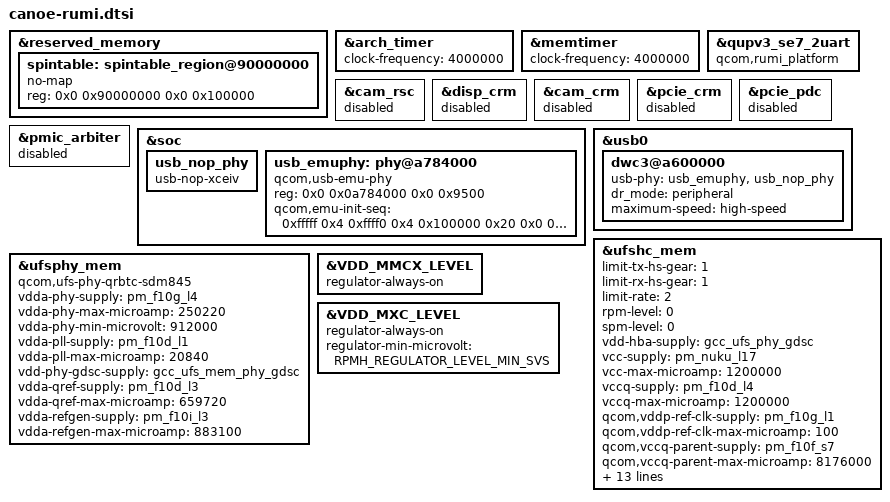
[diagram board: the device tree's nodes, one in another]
// SPDX-License-Identifier: BSD-3-Clause
/*
 * Copyright (c) 2024 Qualcomm Innovation Center, Inc. All rights reserved.
 */
#include <dt-bindings/gpio/gpio.h>
#include <dt-bindings/clock/qcom,gcc-canoe.h>
#include <dt-bindings/clock/qcom,rpmh.h>
#include <dt-bindings/regulator/qcom,rpmh-regulator-levels.h>

#include "canoe-pmic-overlay.dtsi"

&reserved_memory {
	spintable: spintable_region@90000000 {
		no-map;
		reg = <0x0 0x90000000 0x0 0x100000>;
	};
};

&arch_timer {
	clock-frequency = <4000000>;
};

&memtimer {
	clock-frequency = <4000000>;
};

&qupv3_se7_2uart {
	qcom,rumi_platform;
};

&cam_rsc {
	status = "disabled";
};

&disp_crm {
	status = "disabled";
};

&cam_crm {
	status = "disabled";
};

&pcie_crm {
	status = "disabled";
};

&pcie_pdc {
	status = "disabled";
};

&pmic_arbiter {
	status = "disabled";
};

&soc {
	usb_nop_phy: usb_nop_phy {
		compatible = "usb-nop-xceiv";
	};

	usb_emuphy: phy@a784000 {
		compatible = "qcom,usb-emu-phy";
		reg = <0x0 0x0a784000 0x0 0x9500>;

		qcom,emu-init-seq = <0xfffff 0x4
			0xffff0 0x4
			0x100000 0x20
			0x0 0x20
			0x000101F0 0x20
			0x00100000 0x3c
			0x0 0x3c
			0x0 0x4>;
	};
};

&usb0 {
	dwc3@a600000 {
		usb-phy = <&usb_emuphy>, <&usb_nop_phy>;
		dr_mode = "peripheral";
		maximum-speed = "high-speed";
	};
};

&ufsphy_mem {
	compatible = "qcom,ufs-phy-qrbtc-sdm845";

	/* VDDA_UFS_CORE */
	vdda-phy-supply = <&pm_f10g_l4>;
	vdda-phy-max-microamp = <250220>;
	/*
	 * Platforms supporting Gear 5 && Rate B require a different
	 * voltage supply. Check the Power Grid document.
	 */
	vdda-phy-min-microvolt = <912000>;

	/* VDDA_UFS_0_1P2 */
	vdda-pll-supply = <&pm_f10d_l1>;
	vdda-pll-max-microamp = <20840>;

	/* Phy GDSC for VDD_MX, always on */
	vdd-phy-gdsc-supply = <&gcc_ufs_mem_phy_gdsc>;

	/* Qref power supply, Refer Qref diagram */
	vdda-qref-supply = <&pm_f10d_l3>;
	vdda-qref-max-microamp = <659720>;

	/*
	 * Refer to Canoe's Power Grid Analysis document.
	 * Add vote for REFGEN_VDD_A_0P9/VDD_A_PCIE_0_0P9 regulator.
	 */
	vdda-refgen-supply = <&pm_f10i_l3>;
	vdda-refgen-max-microamp = <883100>;

	status = "ok";
};

&ufshc_mem {
	limit-tx-hs-gear = <1>;
	limit-rx-hs-gear = <1>;
	limit-rate = <2>; /* HS Rate-B */
	rpm-level = <0>;
	spm-level = <0>;

	vdd-hba-supply = <&gcc_ufs_phy_gdsc>;

	vcc-supply = <&pm_nuku_l17>;
	vcc-max-microamp = <1200000>;

	vccq-supply = <&pm_f10d_l4>;
	vccq-max-microamp = <1200000>;

	/* UFS Rst pin is always on. It is shared with VDD_PX14 */
	qcom,vddp-ref-clk-supply = <&pm_f10g_l1>;
	qcom,vddp-ref-clk-max-microamp = <100>;

	qcom,vccq-parent-supply = <&pm_f10f_s7>;
	qcom,vccq-parent-max-microamp = <8176000>;

	reset-gpios = <&tlmm 217 GPIO_ACTIVE_LOW>;

	resets = <&gcc GCC_UFS_PHY_BCR>;
	reset-names = "rst";


	clock-names =
		"core_clk",
		"bus_aggr_clk",
		"iface_clk",
		"core_clk_unipro",
		"core_clk_ice",
		"ref_clk",
		"tx_lane0_sync_clk",
		"rx_lane0_sync_clk",
		"rx_lane1_sync_clk";
	clocks =
		<&gcc GCC_UFS_PHY_AXI_CLK>,
		<&gcc GCC_AGGRE_UFS_PHY_AXI_CLK>,
		<&gcc GCC_UFS_PHY_AHB_CLK>,
		<&gcc GCC_UFS_PHY_UNIPRO_CORE_CLK>,
		<&gcc GCC_UFS_PHY_ICE_CORE_CLK>,
		<&rpmhcc RPMH_CXO_CLK>,
		<&gcc GCC_UFS_PHY_TX_SYMBOL_0_CLK>,
		<&gcc GCC_UFS_PHY_RX_SYMBOL_0_CLK>,
		<&gcc GCC_UFS_PHY_RX_SYMBOL_1_CLK>;

	qcom,disable-lpm;
	qcom,iommu-dma = "bypass";

	status = "ok";
};

&VDD_MMCX_LEVEL {
	regulator-always-on;
};

&VDD_MXC_LEVEL {
	regulator-always-on;
	regulator-min-microvolt = <RPMH_REGULATOR_LEVEL_MIN_SVS>;
};
